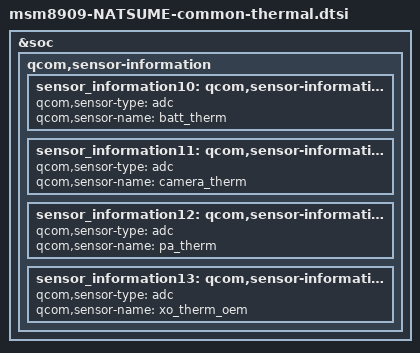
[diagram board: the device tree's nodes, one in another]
/*
 * This software is contributed or developed by KYOCERA Corporation.
 * (C) 2019 KYOCERA Corporation
 *
 * This program is free software; you can redistribute it and/or modify
 * it under the terms of the GNU General Public License version 2 and
 * only version 2 as published by the Free Software Foundation.
 *
 * This program is distributed in the hope that it will be useful,
 * but WITHOUT ANY WARRANTY; without even the implied warranty of
 * MERCHANTABILITY or FITNESS FOR A PARTICULAR PURPOSE.  See the
 * GNU General Public License for more details.
 */

&soc {
	qcom,sensor-information {

		sensor_information10: qcom,sensor-information-10 {
			qcom,sensor-type = "adc";
			qcom,sensor-name = "batt_therm";
		};
		sensor_information11: qcom,sensor-information-11 {
			qcom,sensor-type = "adc";
			qcom,sensor-name = "camera_therm";
		};
		sensor_information12: qcom,sensor-information-12 {
			qcom,sensor-type = "adc";
			qcom,sensor-name = "pa_therm";
		};
		sensor_information13: qcom,sensor-information-13 {
			qcom,sensor-type = "adc";
			qcom,sensor-name = "xo_therm_oem";
		};
	};
};
